# STM32H757xx_CM7 register map
File version: 1.0
Registers are 32-bit, read-write, reset 0x0 unless marked. A register's access mark holds for its fields unless they carry their own. Offsets are from the block's base; [hi:lo] are bit positions; {n}, {i} and the like mark numbered series.

## TIM6 — TIM
Base 0x40001000
Same registers: TIM7 0x40001400
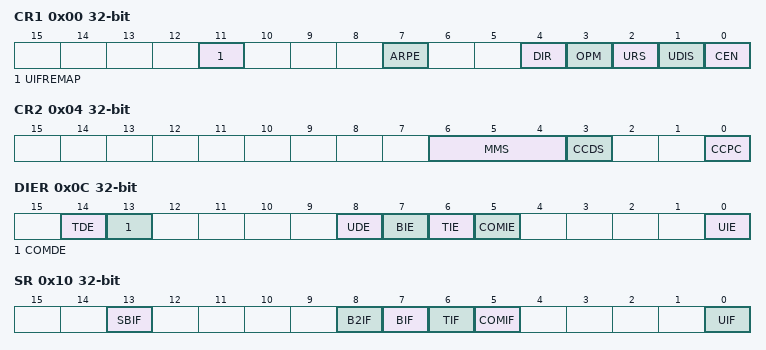
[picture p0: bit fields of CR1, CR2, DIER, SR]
0x00 CR1 — TIM control register 1
  [11] UIFREMAP — Update interrupt flag remap
  [7] ARPE — Auto-reload preload enable
  [4] DIR — Direction
    0=UP (Timer counter counts up); 1=DOWN (Timer counter counts down)
  [3] OPM — One pulse mode
    1=SINGLE (Counter stops counting at the next update event); 0=REPETITIVE (Counter is not stopped at update event)
  [2] URS — Update request source
    0=REGULAR (Counter overflow/underflow, Setting the UG bit or Update generation through the slave mode controller generates an update request); 1=COUNTER (Only counter overflow/underflow generates an update request)
  [1] UDIS — Update disable
  [0] CEN — Counter enable
0x04 CR2 — TIM control register 2
  [6:4] MMS — MMS[2:0] bits (Master Mode Selection)
    0=RESET (UG bit from the TIMx_EGR register is used as trigger output); 1=ENABLE (Counter Enable signal (CNT_EN) is used as trigger output); 2=UPDATE (Update event is used as trigger output); 3=CC1IF (CC1 capture or a compare match is used as trigger output); {v}=OC{v-3}REF (OC{v-3}REF signal is used as trigger output) (v=4..7)
  [3] CCDS — Capture/Compare DMA Selection
    0=CC (CCx DMA request sent when CCx event occurs); 1=UPDATE (CCx DMA requests sent when update event occurs)
  [0] CCPC — Capture/Compare Preloaded Control
0x0C DIER — TIM DMA/interrupt enable register
  [14] TDE — Trigger DMA request enable
  [13] COMDE — COM DMA request enable
  [8] UDE — Update DMA request enable
  [7] BIE — Break interrupt enable
  [6] TIE — Trigger interrupt enable
  [5] COMIE — COM interrupt enable
  [0] UIE — Update interrupt enable
0x10 SR — TIM status register
  [13] SBIF — System Break Flag
  [8] B2IF — Break2 interrupt Flag
  [7] BIF — Break interrupt Flag
  [6] TIF — Trigger interrupt Flag
  [5] COMIF — COM interrupt Flag
  [0] UIF — Update interrupt Flag
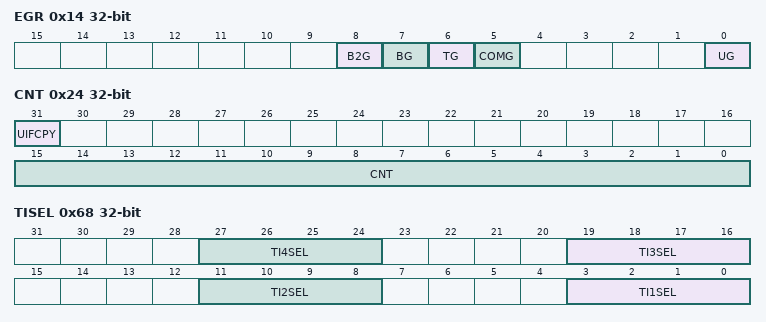
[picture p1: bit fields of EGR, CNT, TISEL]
0x14 EGR — TIM event generation register
  [8] B2G — Break Generation
  [7] BG — Break Generation
  [6] TG — Trigger Generation
  [5] COMG — Capture/Compare Control Update Generation
  [0] UG — Update Generation
0x24 CNT — TIM counter register
  [31] UIFCPY — Update interrupt flag copy
  [15:0] CNT — Counter Value
0x28 PSC — TIM prescaler
  [15:0] PSC — Prescaler Value
0x2C ARR — TIM auto-reload register
  [15:0] ARR — actual auto-reload Value
0x4C DMAR — TIM DMA address for full transfer
  [15:0] DMAB — DMA register for burst accesses
0x60 AF1 — TIM alternate function option register 1
0x64 AF2 — TIM alternate function option register 2
0x68 TISEL — TIM Input Selection register
  [8n-5:8n-8] TI{n}SEL (n=1..4) — TI{n}SEL[3:0] bits (TIM TI{n} SEL)

## WWDG2 — Window WATCHDOG
Base 0x40002C00
Same registers: WWDG1 0x50003000
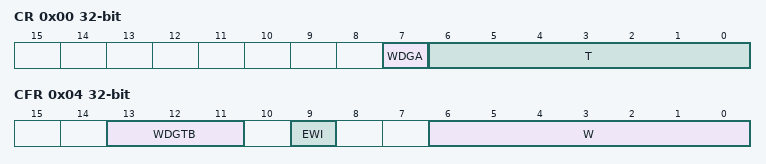
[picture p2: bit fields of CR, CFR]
0x00 CR — WWDG Control register
  [7] WDGA — Activation bit
  [6:0] T — T[6:0] bits (7-Bit counter (MSB to LSB))
0x04 CFR — WWDG Configuration register
  [13:11] WDGTB — WDGTB[2:0] bits (Timer Base)
    0=PRESCALER_1 (WWDG counter clock = (PCLK1/4096)/1); 1=PRESCALER_2 (WWDG counter clock = (PCLK1/4096)/2); 2=PRESCALER_4 (WWDG counter clock = (PCLK1/4096)/4); 3=PRESCALER_8 (WWDG counter clock = (PCLK1/4096)/8); 4=PRESCALER_16 (WWDG counter clock = (PCLK1/4096)/16); 5=PRESCALER_32 (WWDG counter clock = (PCLK1/4096)/32); 6=PRESCALER_64 (WWDG counter clock = (PCLK1/4096)/64); 7=PRESCALER_128 (WWDG counter clock = (PCLK1/4096)/128)
  [9] EWI — Early Wakeup Interrupt
  [6:0] W — W[6:0] bits (7-bit window value)
0x08 SR — WWDG Status register
  [0] EWIF — Early Wakeup Interrupt Flag

## SPDIFRX — SPDIF-RX Interface
Base 0x40004000
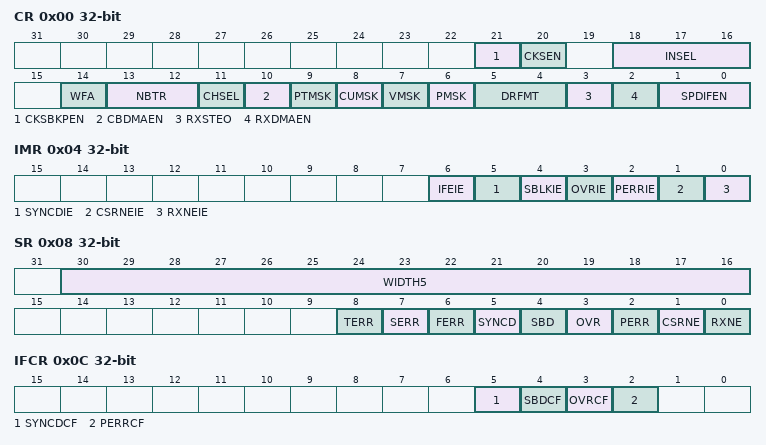
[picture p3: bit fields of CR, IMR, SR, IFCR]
0x00 CR — Control register
  [21] CKSBKPEN — Backup Symbol Clock Enable
  [20] CKSEN — Symbol Clock Enable
  [18:16] INSEL — SPDIF input selection
  [14] WFA — Wait For Activity
  [13:12] NBTR — Maximum allowed re-tries during synchronization phase
  [11] CHSEL — Channel Selection
  [10] CBDMAEN — Control Buffer DMA ENable for control flow
  [9] PTMSK — Mask of Preamble Type bits
  [8] CUMSK — Mask of channel status and user bits
  [7] VMSK — Mask of Validity bit
  [6] PMSK — Mask Parity error bit
  [5:4] DRFMT — RX Data format
  [3] RXSTEO — Stereo Mode
  [2] RXDMAEN — Receiver DMA Enable for data flow
  [1:0] SPDIFEN — Peripheral Block Enable
0x04 IMR — Interrupt mask register
  [6] IFEIE — Serial Interface Error Interrupt Enable
  [5] SYNCDIE — Synchronization Done
  [4] SBLKIE — Synchronization Block Detected Interrupt Enable
  [3] OVRIE — Overrun error Interrupt Enable
  [2] PERRIE — Parity error interrupt enable
  [1] CSRNEIE — Control Buffer Ready Interrupt Enable
  [0] RXNEIE — RXNE interrupt enable
0x08 SR — Status register
  [30:16] WIDTH5 — Duration of 5 symbols counted with spdif_clk
  [8] TERR — Time-out error
  [7] SERR — Synchronization error
  [6] FERR — Framing error
  [5] SYNCD — Synchronization Done
  [4] SBD — Synchronization Block Detected
  [3] OVR — Overrun error
  [2] PERR — Parity error
  [1] CSRNE — The Control Buffer register is not empty
  [0] RXNE — Read data register not empty
0x0C IFCR — Interrupt Flag Clear register
  [5] SYNCDCF — Clears the Synchronization Done flag
  [4] SBDCF — Clears the Synchronization Block Detected flag
  [3] OVRCF — Clears the Overrun error flag
  [2] PERRCF — Clears the Parity error flag
0x10 DR — Data input register
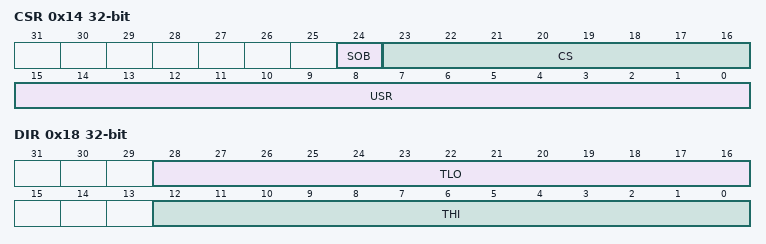
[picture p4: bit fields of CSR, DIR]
0x14 CSR — Channel Status register
  [24] SOB — Start Of Block
  [23:16] CS — Channel A status information
  [15:0] USR — User data information
0x18 DIR — Debug Information register
  [28:16] TLO — Threshold HIGH
  [12:0] THI — Threshold LOW
